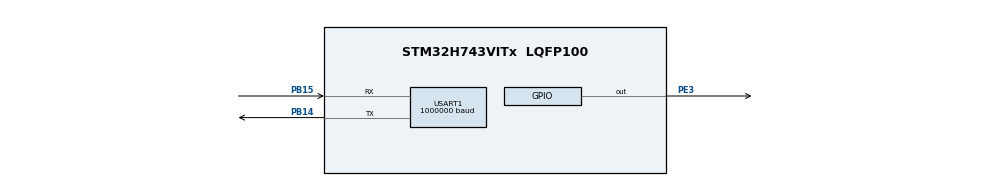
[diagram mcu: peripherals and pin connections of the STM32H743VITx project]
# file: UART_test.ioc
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Mcu.Family=STM32H7
Mcu.Name=STM32H743VITx
Mcu.Package=LQFP100
NVIC.PriorityGroup=NVIC_PRIORITYGROUP_4
NVIC.USART1_IRQn=true\:0\:0\:false\:false\:true\:true\:true\:true
PB14.Mode=Asynchronous
PB14.Signal=USART1_TX
PB15.Mode=Asynchronous
PB15.Signal=USART1_RX
PE3.Signal=GPIO_Output
PH0-OSC_IN\ (PH0).Mode=HSE-External-Oscillator
PH0-OSC_IN\ (PH0).Signal=RCC_OSC_IN
PH1-OSC_OUT\ (PH1).Mode=HSE-External-Oscillator
PH1-OSC_OUT\ (PH1).Signal=RCC_OSC_OUT
ProjectManager.HeapSize=0x200
ProjectManager.StackSize=0x400
ProjectManager.TargetToolchain=STM32CubeIDE
RCC.ADCFreq_Value=50390625
RCC.APB1Freq_Value=100000000
RCC.APB2Freq_Value=100000000
RCC.APB3Freq_Value=100000000
RCC.APB4Freq_Value=100000000
RCC.CortexFreq_Value=100000000
RCC.DIVM1=5
RCC.DIVN1=40
RCC.HCLKFreq_Value=100000000
RCC.HSIDiv=RCC_PLLSAIDIVR_2
RCC.PLLSourceVirtual=RCC_PLLSOURCE_HSE
RCC.SYSCLKFreq_VALUE=100000000
RCC.SYSCLKSource=RCC_SYSCLKSOURCE_PLLCLK
RCC.USART16CLockSelection=RCC_USART16CLKSOURCE_HSI
RCC.USBFreq_Value=100000000
USART1.BaudRate=1000000
USART1.VirtualMode-Asynchronous=VM_ASYNC
board=custom

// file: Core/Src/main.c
/* USER CODE BEGIN Header */
/**
  ******************************************************************************
  * @file           : main.c
  * @brief          : Main program body
  ******************************************************************************
  * @attention
  *
  * Copyright (c) 2026 STMicroelectronics.
  * All rights reserved.
  *
  * This software is licensed under terms that can be found in the LICENSE file
  * in the root directory of this software component.
  * If no LICENSE file comes with this software, it is provided AS-IS.
  *
  ******************************************************************************
  */
/* USER CODE END Header */
#include "main.h"

/* USER CODE BEGIN Includes */
#define PACKET_PREAMBLE  0x24
#define PACKET_TERMINATOR 0x0A
#define PACKET_SIZE 3
/* USER CODE END Includes */

UART_HandleTypeDef huart1;

/* USER CODE BEGIN PV */
uint8_t rx_buffer[PACKET_SIZE];
uint8_t rx_index = 0;
volatile uint8_t packet_ready = 0;
volatile uint8_t received_data = 0;
/* USER CODE END PV */

void SystemClock_Config(void);
static void MX_GPIO_Init(void);
static void MX_USART1_UART_Init(void);

/* USER CODE BEGIN 0 */
void HAL_UART_RxCpltCallback(UART_HandleTypeDef *huart)
{
          if(huart == &huart1)
          {
        	  if(rx_index == 0){
                  if (rx_buffer[0] != PACKET_PREAMBLE) {
                      // Ð?ÐµÐ¿Ñ€Ð°Ð²Ð¸Ð»ÑŒÐ½Ð°Ñ? Ð¿Ñ€ÐµÐ°Ð¼Ð±ÑƒÐ»Ð° - Ñ?Ð±Ñ€Ð°Ñ?Ñ‹Ð²Ð°ÐµÐ¼ Ð¸ Ð¶Ð´ÐµÐ¼ Ð·Ð°Ð½Ð¾Ð²Ð¾
                      rx_index = 0;
                      HAL_UART_Receive_IT(&huart1, &rx_buffer[rx_index], 1);
                      return;
                  }
        	  }

              rx_index++;
              // Ð•Ñ?Ð»Ð¸ Ð¿Ñ€Ð¸Ð½Ñ?Ð»Ð¸ Ð²ÐµÑ?ÑŒ Ð¿Ð°ÐºÐµÑ‚
              if (rx_index >= PACKET_SIZE) {
                  // ÐŸÑ€Ð¾Ð²ÐµÑ€Ñ?ÐµÐ¼ Ñ‚ÐµÑ€Ð¼Ð¸Ð½Ð°Ñ‚Ð¾Ñ€
                  if (rx_buffer[2] == PACKET_TERMINATOR) {
                      packet_ready = 1;
                      received_data = rx_buffer[1];
                  }
                  rx_index = 0;  // Ð¡Ð±Ñ€Ð¾Ñ? Ð´Ð»Ñ? Ñ?Ð»ÐµÐ´ÑƒÑŽÑ‰ÐµÐ³Ð¾ Ð¿Ð°ÐºÐµÑ‚Ð°
              }

              HAL_UART_Receive_IT(&huart1, &rx_buffer[rx_index], 1);
//              HAL_UART_Receive_IT(&huart1, (uint8_t*)RX, 1);
          }
}
/* USER CODE END 0 */

int main(void)
{

  /* MCU Configuration--------------------------------------------------------*/

  /* Reset of all peripherals, Initializes the Flash interface and the Systick. */
  HAL_Init();

  /* Configure the system clock */
  SystemClock_Config();

  /* Initialize all configured peripherals */
  MX_GPIO_Init();
  MX_USART1_UART_Init();
  /* USER CODE BEGIN 2 */
  HAL_UART_Receive_IT(&huart1, &rx_buffer[0], 3);
  /* USER CODE END 2 */

  /* Infinite loop */
  while (1)
  {

    /* USER CODE BEGIN 3 */
	  if(packet_ready){
		  packet_ready = 0;
	 	  HAL_UART_Transmit_IT(&huart1,  (uint8_t *)received_data, 1);
	        if (received_data == 0x01) {
	            HAL_GPIO_WritePin(GPIOE, GPIO_PIN_3, GPIO_PIN_SET);
	        } else if (received_data == 0x00) {
	            HAL_GPIO_WritePin(GPIOE, GPIO_PIN_3, GPIO_PIN_RESET);
	        }
	  }

  }
  /* USER CODE END 3 */
}

void SystemClock_Config(void)
{
  RCC_OscInitTypeDef RCC_OscInitStruct = {0};
  RCC_ClkInitTypeDef RCC_ClkInitStruct = {0};

  /** Supply configuration update enable
  */
  HAL_PWREx_ConfigSupply(PWR_LDO_SUPPLY);

  /** Configure the main internal regulator output voltage
  */
  __HAL_PWR_VOLTAGESCALING_CONFIG(PWR_REGULATOR_VOLTAGE_SCALE3);

  while(!__HAL_PWR_GET_FLAG(PWR_FLAG_VOSRDY)) {}

  /** Initializes the RCC Oscillators according to the specified parameters
  * in the RCC_OscInitTypeDef structure.
  */
  RCC_OscInitStruct.OscillatorType = RCC_OSCILLATORTYPE_HSI|RCC_OSCILLATORTYPE_HSE;
  RCC_OscInitStruct.HSEState = RCC_HSE_ON;
  RCC_OscInitStruct.HSIState = RCC_HSI_DIV2;
  RCC_OscInitStruct.HSICalibrationValue = RCC_HSICALIBRATION_DEFAULT;
  RCC_OscInitStruct.PLL.PLLState = RCC_PLL_ON;
  RCC_OscInitStruct.PLL.PLLSource = RCC_PLLSOURCE_HSE;
  RCC_OscInitStruct.PLL.PLLM = 5;
  RCC_OscInitStruct.PLL.PLLN = 40;
  RCC_OscInitStruct.PLL.PLLP = 2;
  RCC_OscInitStruct.PLL.PLLQ = 2;
  RCC_OscInitStruct.PLL.PLLR = 2;
  RCC_OscInitStruct.PLL.PLLRGE = RCC_PLL1VCIRANGE_2;
  RCC_OscInitStruct.PLL.PLLVCOSEL = RCC_PLL1VCOWIDE;
  RCC_OscInitStruct.PLL.PLLFRACN = 0;
  if (HAL_RCC_OscConfig(&RCC_OscInitStruct) != HAL_OK)
  {
    Error_Handler();
  }

  /** Initializes the CPU, AHB and APB buses clocks
  */
  RCC_ClkInitStruct.ClockType = RCC_CLOCKTYPE_HCLK|RCC_CLOCKTYPE_SYSCLK
                              |RCC_CLOCKTYPE_PCLK1|RCC_CLOCKTYPE_PCLK2
                              |RCC_CLOCKTYPE_D3PCLK1|RCC_CLOCKTYPE_D1PCLK1;
  RCC_ClkInitStruct.SYSCLKSource = RCC_SYSCLKSOURCE_PLLCLK;
  RCC_ClkInitStruct.SYSCLKDivider = RCC_SYSCLK_DIV1;
  RCC_ClkInitStruct.AHBCLKDivider = RCC_HCLK_DIV1;
  RCC_ClkInitStruct.APB3CLKDivider = RCC_APB3_DIV1;
  RCC_ClkInitStruct.APB1CLKDivider = RCC_APB1_DIV1;
  RCC_ClkInitStruct.APB2CLKDivider = RCC_APB2_DIV1;
  RCC_ClkInitStruct.APB4CLKDivider = RCC_APB4_DIV1;

  if (HAL_RCC_ClockConfig(&RCC_ClkInitStruct, FLASH_LATENCY_2) != HAL_OK)
  {
    Error_Handler();
  }
}

static void MX_USART1_UART_Init(void)
{

  huart1.Instance = USART1;
  huart1.Init.BaudRate = 1000000;
  huart1.Init.WordLength = UART_WORDLENGTH_8B;
  huart1.Init.StopBits = UART_STOPBITS_1;
  huart1.Init.Parity = UART_PARITY_NONE;
  huart1.Init.Mode = UART_MODE_TX_RX;
  huart1.Init.HwFlowCtl = UART_HWCONTROL_NONE;
  huart1.Init.OverSampling = UART_OVERSAMPLING_16;
  huart1.Init.OneBitSampling = UART_ONE_BIT_SAMPLE_DISABLE;
  huart1.Init.ClockPrescaler = UART_PRESCALER_DIV1;
  huart1.AdvancedInit.AdvFeatureInit = UART_ADVFEATURE_NO_INIT;
  if (HAL_UART_Init(&huart1) != HAL_OK)
  {
    Error_Handler();
  }
  if (HAL_UARTEx_SetTxFifoThreshold(&huart1, UART_TXFIFO_THRESHOLD_1_8) != HAL_OK)
  {
    Error_Handler();
  }
  if (HAL_UARTEx_SetRxFifoThreshold(&huart1, UART_RXFIFO_THRESHOLD_1_8) != HAL_OK)
  {
    Error_Handler();
  }
  if (HAL_UARTEx_DisableFifoMode(&huart1) != HAL_OK)
  {
    Error_Handler();
  }

}

static void MX_GPIO_Init(void)
{
  GPIO_InitTypeDef GPIO_InitStruct = {0};

  /* GPIO Ports Clock Enable */
  __HAL_RCC_GPIOE_CLK_ENABLE();
  __HAL_RCC_GPIOH_CLK_ENABLE();
  __HAL_RCC_GPIOB_CLK_ENABLE();

  /*Configure GPIO pin Output Level */
  HAL_GPIO_WritePin(GPIOE, GPIO_PIN_3, GPIO_PIN_RESET);

  /*Configure GPIO pin : PE3 */
  GPIO_InitStruct.Pin = GPIO_PIN_3;
  GPIO_InitStruct.Mode = GPIO_MODE_OUTPUT_PP;
  GPIO_InitStruct.Pull = GPIO_NOPULL;
  GPIO_InitStruct.Speed = GPIO_SPEED_FREQ_LOW;
  HAL_GPIO_Init(GPIOE, &GPIO_InitStruct);

}

void Error_Handler(void)
{
  __disable_irq();
  while (1)
  {
  }
}
